# PIC32MM0256GPM036 register map
Vendor: Microchip
Registers are 32-bit, read-write, reset 0x0 unless marked. A register's access mark holds for its fields unless they carry their own. Addresses are absolute, and some are shared; only a register's first bit layout is shown; [hi:lo] are bit positions.

## CCP8
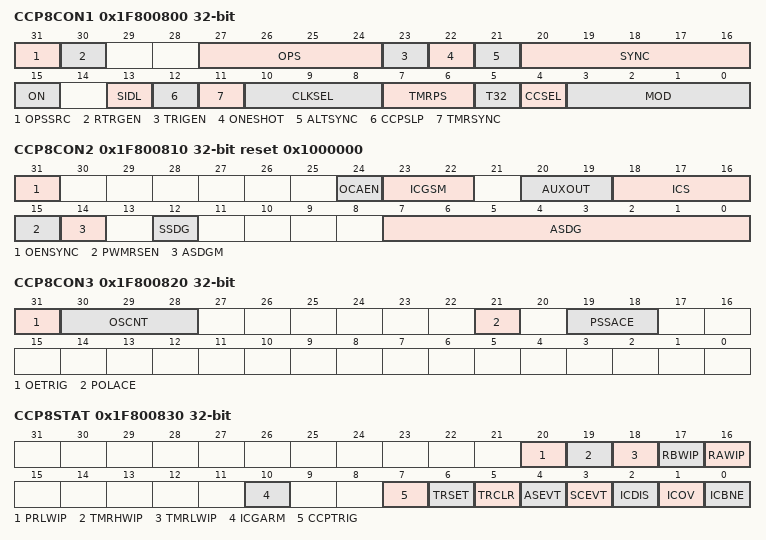
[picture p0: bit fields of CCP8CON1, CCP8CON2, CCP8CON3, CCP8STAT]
0x1F800800 CCP8CON1
  [31] OPSSRC, [30] RTRGEN, [27:24] OPS, [23] TRIGEN, [22] ONESHOT, [21] ALTSYNC, [20:16] SYNC, [15] ON, [13] SIDL, [12] CCPSLP, [11] TMRSYNC, [10:8] CLKSEL, [7:6] TMRPS, [5] T32, [4] CCSEL, [3:0] MOD
0x1F800810 CCP8CON2 reset 0x1000000
  [31] OENSYNC, [24] OCAEN, [23:22] ICGSM, [20:19] AUXOUT, [18:16] ICS, [15] PWMRSEN, [14] ASDGM, [12] SSDG, [7:0] ASDG
0x1F800820 CCP8CON3
  [31] OETRIG, [30:28] OSCNT, [21] POLACE, [19:18] PSSACE
0x1F800830 CCP8STAT
  [20] PRLWIP
  [19] TMRHWIP
  [18] TMRLWIP
  [17] RBWIP
  [16] RAWIP
  [10] ICGARM
  [7] CCPTRIG ro
  [6] TRSET
  [5] TRCLR
  [4] ASEVT — (can only be cleared)
  [3] SCEVT — (can only be cleared)
  [2] ICDIS ro
  [1] ICOV — (can only be cleared)
  [0] ICBNE ro
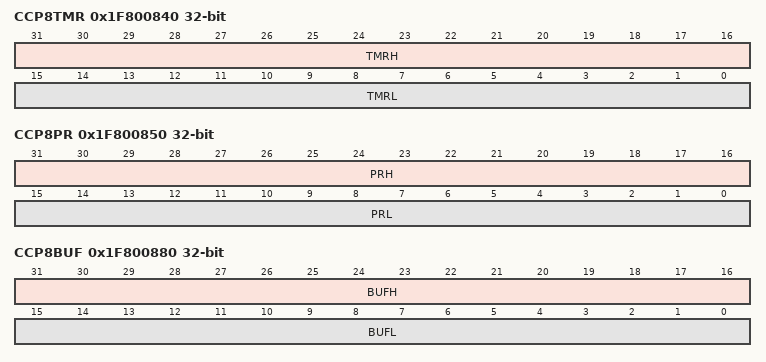
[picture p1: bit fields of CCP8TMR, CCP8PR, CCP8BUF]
0x1F800840 CCP8TMR
  [31:16] TMRH, [15:0] TMRL
0x1F800850 CCP8PR
  [31:16] PRH, [15:0] PRL
0x1F800860 CCP8RA
  [15:0] CMPA
0x1F800870 CCP8RB
  [15:0] CMPB
0x1F800880 CCP8BUF
  [31:16] BUFH, [15:0] BUFL

## CCP9
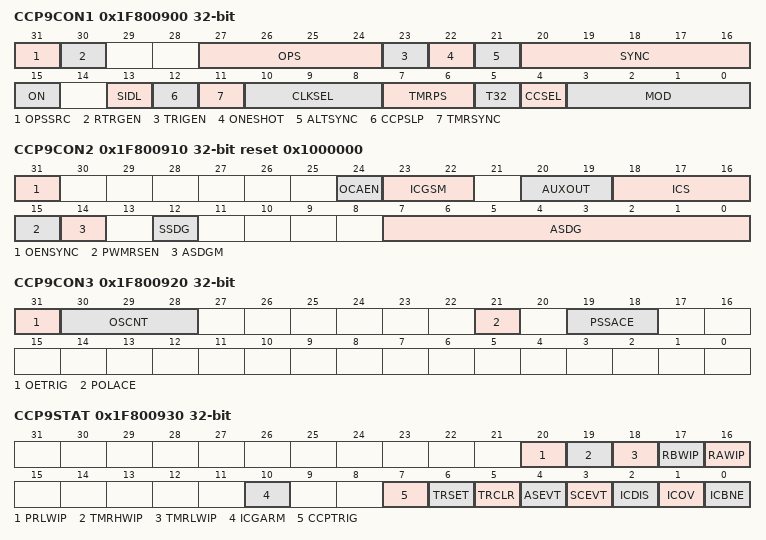
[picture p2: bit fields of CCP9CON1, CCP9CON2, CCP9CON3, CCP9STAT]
0x1F800900 CCP9CON1
  [31] OPSSRC, [30] RTRGEN, [27:24] OPS, [23] TRIGEN, [22] ONESHOT, [21] ALTSYNC, [20:16] SYNC, [15] ON, [13] SIDL, [12] CCPSLP, [11] TMRSYNC, [10:8] CLKSEL, [7:6] TMRPS, [5] T32, [4] CCSEL, [3:0] MOD
0x1F800910 CCP9CON2 reset 0x1000000
  [31] OENSYNC, [24] OCAEN, [23:22] ICGSM, [20:19] AUXOUT, [18:16] ICS, [15] PWMRSEN, [14] ASDGM, [12] SSDG, [7:0] ASDG
0x1F800920 CCP9CON3
  [31] OETRIG, [30:28] OSCNT, [21] POLACE, [19:18] PSSACE
0x1F800930 CCP9STAT
  [20] PRLWIP
  [19] TMRHWIP
  [18] TMRLWIP
  [17] RBWIP
  [16] RAWIP
  [10] ICGARM
  [7] CCPTRIG ro
  [6] TRSET
  [5] TRCLR
  [4] ASEVT — (can only be cleared)
  [3] SCEVT — (can only be cleared)
  [2] ICDIS ro
  [1] ICOV — (can only be cleared)
  [0] ICBNE ro
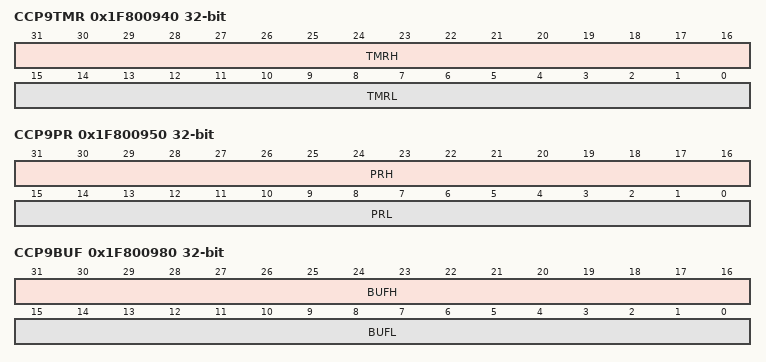
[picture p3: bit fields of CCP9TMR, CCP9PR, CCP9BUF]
0x1F800940 CCP9TMR
  [31:16] TMRH, [15:0] TMRL
0x1F800950 CCP9PR
  [31:16] PRH, [15:0] PRL
0x1F800960 CCP9RA
  [15:0] CMPA
0x1F800970 CCP9RB
  [15:0] CMPB
0x1F800980 CCP9BUF
  [31:16] BUFH, [15:0] BUFL

## I2C1
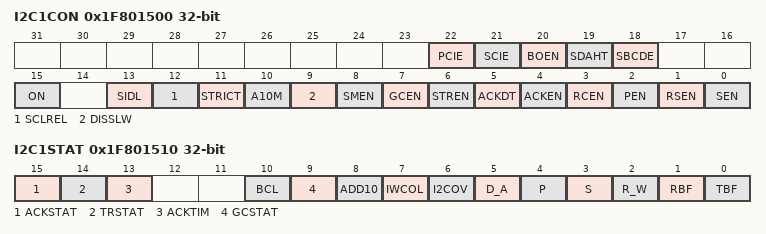
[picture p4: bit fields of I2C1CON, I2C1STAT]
0x1F801500 I2C1CON reset not defined — (power-on value ---------00000--0x01000000000000)
  [22] PCIE, [21] SCIE, [20] BOEN, [19] SDAHT, [18] SBCDE, [15] ON, [13] SIDL, [12] SCLREL, [11] STRICT, [10] A10M, [9] DISSLW, [8] SMEN, [7] GCEN, [6] STREN, [5] ACKDT, [4] ACKEN, [3] RCEN, [2] PEN, [1] RSEN, [0] SEN
0x1F801510 I2C1STAT
  [15] ACKSTAT ro
  [14] TRSTAT ro
  [13] ACKTIM ro
  [10] BCL — (can only be cleared)
  [9] GCSTAT ro
  [8] ADD10 ro
  [7] IWCOL — (can only be cleared)
  [6] I2COV — (can only be cleared)
  [5] D_A ro
  [4] P — (can only be cleared)
  [3] S — (can only be cleared)
  [2] R_W ro
  [1] RBF ro
  [0] TBF ro
0x1F801520 I2C1ADD
  [9:0] I2CADD
0x1F801530 I2C1MSK
  [9:0] I2CMSK
0x1F801540 I2C1BRG
  [15:0] I2CBRG
0x1F801550 I2C1TRN wo reset 0xFF
  [7:0] I2CTRN
0x1F801560 I2C1RCV ro
  [7:0] I2CRCV

## I2C2
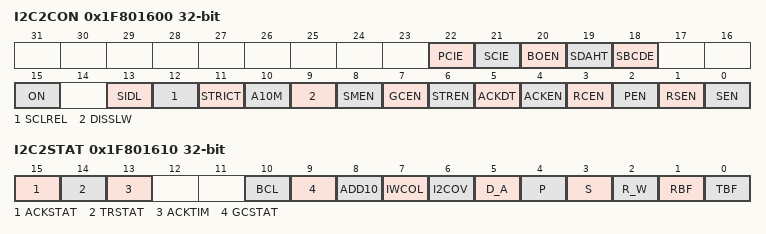
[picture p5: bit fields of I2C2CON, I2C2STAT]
0x1F801600 I2C2CON reset not defined — (power-on value ---------00000--0x01000000000000)
  [22] PCIE, [21] SCIE, [20] BOEN, [19] SDAHT, [18] SBCDE, [15] ON, [13] SIDL, [12] SCLREL, [11] STRICT, [10] A10M, [9] DISSLW, [8] SMEN, [7] GCEN, [6] STREN, [5] ACKDT, [4] ACKEN, [3] RCEN, [2] PEN, [1] RSEN, [0] SEN
0x1F801610 I2C2STAT
  [15] ACKSTAT ro
  [14] TRSTAT ro
  [13] ACKTIM ro
  [10] BCL — (can only be cleared)
  [9] GCSTAT ro
  [8] ADD10 ro
  [7] IWCOL — (can only be cleared)
  [6] I2COV — (can only be cleared)
  [5] D_A ro
  [4] P — (can only be cleared)
  [3] S — (can only be cleared)
  [2] R_W ro
  [1] RBF ro
  [0] TBF ro
0x1F801620 I2C2ADD
  [9:0] I2CADD
0x1F801630 I2C2MSK
  [9:0] I2CMSK
0x1F801640 I2C2BRG
  [15:0] I2CBRG
0x1F801650 I2C2TRN wo reset 0xFF
  [7:0] I2CTRN
0x1F801660 I2C2RCV ro
  [7:0] I2CRCV

## I2C3
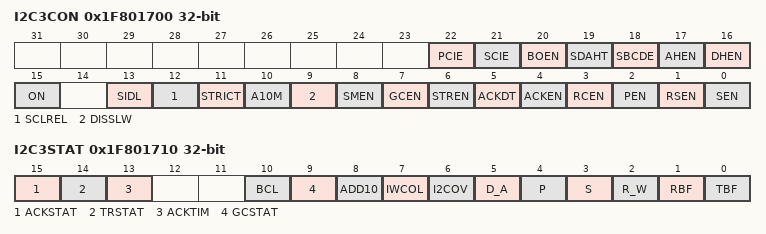
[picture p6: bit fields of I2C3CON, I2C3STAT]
0x1F801700 I2C3CON reset not defined — (power-on value ---------00000000x01000000000000)
  [22] PCIE, [21] SCIE, [20] BOEN, [19] SDAHT, [18] SBCDE, [17] AHEN, [16] DHEN, [15] ON, [13] SIDL, [12] SCLREL, [11] STRICT, [10] A10M, [9] DISSLW, [8] SMEN, [7] GCEN, [6] STREN, [5] ACKDT, [4] ACKEN, [3] RCEN, [2] PEN, [1] RSEN, [0] SEN
0x1F801710 I2C3STAT
  [15] ACKSTAT ro
  [14] TRSTAT ro
  [13] ACKTIM ro
  [10] BCL — (can only be cleared)
  [9] GCSTAT ro
  [8] ADD10 ro
  [7] IWCOL — (can only be cleared)
  [6] I2COV — (can only be cleared)
  [5] D_A ro
  [4] P — (can only be cleared)
  [3] S — (can only be cleared)
  [2] R_W ro
  [1] RBF ro
  [0] TBF ro
0x1F801720 I2C3ADD
  [9:0] I2CADD
0x1F801730 I2C3MSK
  [9:0] I2CMSK
0x1F801740 I2C3BRG
  [15:0] I2CBRG
0x1F801750 I2C3TRN wo reset 0xFF
  [7:0] I2CTRN
0x1F801760 I2C3RCV ro
  [7:0] I2CRCV
